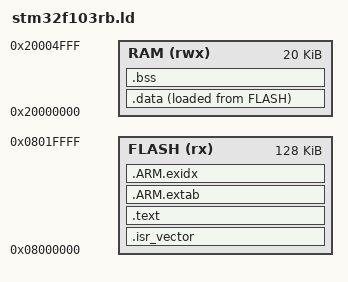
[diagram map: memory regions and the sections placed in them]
ENTRY(Reset_Handler)

MEMORY
{
    FLASH (rx)  : ORIGIN = 0x08000000, LENGTH = 128K
    RAM   (rwx) : ORIGIN = 0x20000000, LENGTH = 20K
}

_estack = ORIGIN(RAM) + LENGTH(RAM);
_stack_size = 2K;

SECTIONS
{
    .isr_vector :
    {
        . = ALIGN(4);
        KEEP(*(.isr_vector))
    } > FLASH

    .text :
    {
        *(.text*)
        *(.rodata*)
        . = ALIGN(4);
    } > FLASH

    .ARM.extab : { *(.ARM.extab*) } > FLASH
    .ARM.exidx : { *(.ARM.exidx*) } > FLASH

    .data :
    {
        . = ALIGN(4);
        _sdata = .;
        *(.data*)
        . = ALIGN(4);
        _edata = .;
    } > RAM AT > FLASH
    _sidata = LOADADDR(.data);

    .bss (NOLOAD) :
    {
        . = ALIGN(4);
        _sbss = .;
        *(.bss*)
        *(COMMON)
        . = ALIGN(4);
        _ebss = .;
    } > RAM

    /DISCARD/ : { *(.note.GNU-stack) *(.comment) }
}

ASSERT(_ebss <= _estack - _stack_size, "RAM data overlaps reserved stack")
ASSERT(SIZEOF(.isr_vector) == (16 + 43) * 4, "Wrong medium-density vector count")

